VERSION ""

NS_ :

BS_:

BU_: a_box Charger OrionBMS DAQ

BO_ 2348816708 can2_precharge_hb: 2 a_box
 SG_ BMS : 8|8@1+ (1,0) [0|0] "" Vector__XXX
 SG_ IMD : 0|8@1+ (1,0) [0|0] "" Vector__XXX

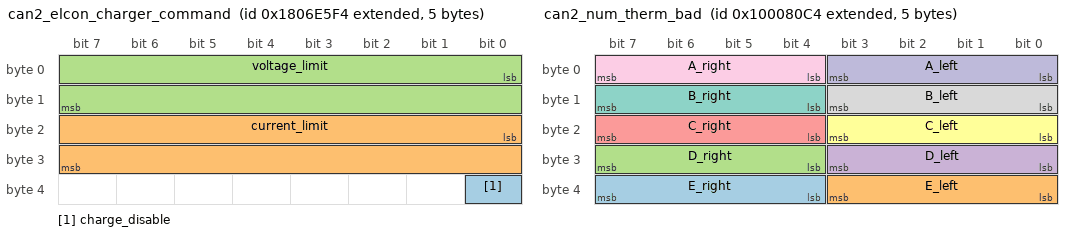
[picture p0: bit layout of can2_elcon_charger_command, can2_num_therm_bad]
BO_ 2550588916 can2_elcon_charger_command: 5 a_box
 SG_ charge_disable : 32|1@1+ (1,0) [0|0] "" Vector__XXX
 SG_ current_limit : 16|16@1+ (0.1,0) [0|0] "A" Vector__XXX
 SG_ voltage_limit : 0|16@1+ (0.1,0) [0|0] "V" Vector__XXX

BO_ 2415952068 can2_num_therm_bad: 5 a_box
 SG_ E_right : 36|4@1+ (1,0) [0|0] "" Vector__XXX
 SG_ E_left : 32|4@1+ (1,0) [0|0] "" Vector__XXX
 SG_ D_right : 28|4@1+ (1,0) [0|0] "" Vector__XXX
 SG_ D_left : 24|4@1+ (1,0) [0|0] "" Vector__XXX
 SG_ C_right : 20|4@1+ (1,0) [0|0] "" Vector__XXX
 SG_ C_left : 16|4@1+ (1,0) [0|0] "" Vector__XXX
 SG_ B_right : 12|4@1+ (1,0) [0|0] "" Vector__XXX
 SG_ B_left : 8|4@1+ (1,0) [0|0] "" Vector__XXX
 SG_ A_right : 4|4@1+ (1,0) [0|0] "" Vector__XXX
 SG_ A_left : 0|4@1+ (1,0) [0|0] "" Vector__XXX

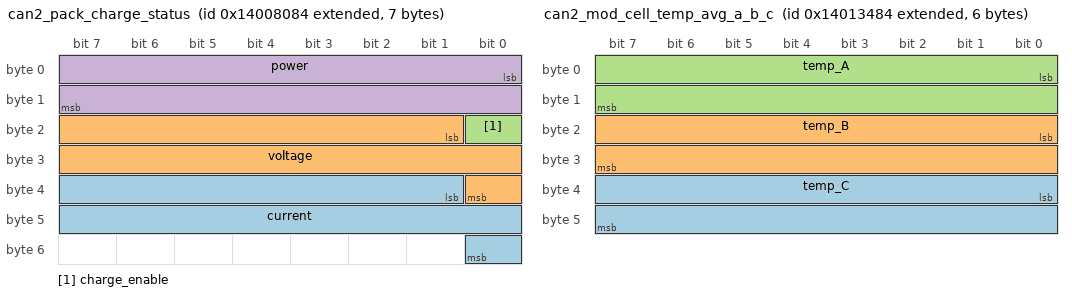
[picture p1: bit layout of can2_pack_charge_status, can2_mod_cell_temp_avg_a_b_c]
BO_ 2483060868 can2_pack_charge_status: 7 a_box
 SG_ current : 33|16@1+ (0.1,0) [0|0] "A" Vector__XXX
 SG_ voltage : 17|16@1+ (0.1,0) [0|0] "V" Vector__XXX
 SG_ charge_enable : 16|1@1+ (1,0) [0|0] "" Vector__XXX
 SG_ power : 0|16@1+ (1,0) [0|0] "W" Vector__XXX

BO_ 2349131268 can2_max_cell_temp: 2 a_box
 SG_ max_temp : 0|16@1- (0.1,0) [0|0] "" Vector__XXX

BO_ 2483106948 can2_mod_cell_temp_avg_a_b_c: 6 a_box
 SG_ temp_C : 32|16@1- (0.1,0) [0|0] "" Vector__XXX
 SG_ temp_B : 16|16@1- (0.1,0) [0|0] "" Vector__XXX
 SG_ temp_A : 0|16@1- (0.1,0) [0|0] "" Vector__XXX

BO_ 2483107012 can2_mod_cell_temp_avg_d_e: 4 a_box
 SG_ temp_E : 16|16@1- (0.1,0) [0|0] "" Vector__XXX
 SG_ temp_D : 0|16@1- (0.1,0) [0|0] "" Vector__XXX

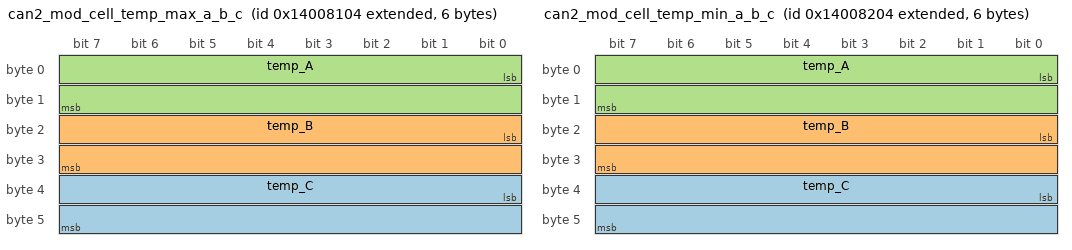
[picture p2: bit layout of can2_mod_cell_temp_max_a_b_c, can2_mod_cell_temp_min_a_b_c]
BO_ 2483060996 can2_mod_cell_temp_max_a_b_c: 6 a_box
 SG_ temp_C : 32|16@1- (0.1,0) [0|0] "" Vector__XXX
 SG_ temp_B : 16|16@1- (0.1,0) [0|0] "" Vector__XXX
 SG_ temp_A : 0|16@1- (0.1,0) [0|0] "" Vector__XXX

BO_ 2483061060 can2_mod_cell_temp_max_d_e: 4 a_box
 SG_ temp_E : 16|16@1- (0.1,0) [0|0] "" Vector__XXX
 SG_ temp_D : 0|16@1- (0.1,0) [0|0] "" Vector__XXX

BO_ 2483061252 can2_mod_cell_temp_min_a_b_c: 6 a_box
 SG_ temp_C : 32|16@1- (0.1,0) [0|0] "" Vector__XXX
 SG_ temp_B : 16|16@1- (0.1,0) [0|0] "" Vector__XXX
 SG_ temp_A : 0|16@1- (0.1,0) [0|0] "" Vector__XXX

BO_ 2483061316 can2_mod_cell_temp_min_d_e: 4 a_box
 SG_ temp_E : 16|16@1- (0.1,0) [0|0] "" Vector__XXX
 SG_ temp_D : 0|16@1- (0.1,0) [0|0] "" Vector__XXX

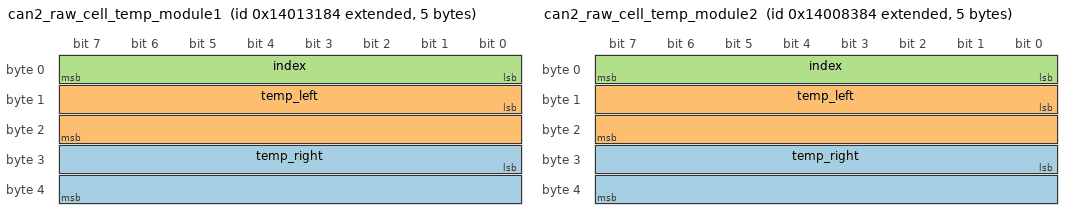
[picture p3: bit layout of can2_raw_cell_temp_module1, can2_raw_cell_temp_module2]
BO_ 2483106180 can2_raw_cell_temp_module1: 5 a_box
 SG_ temp_right : 24|16@1- (0.1,0) [0|0] "C" Vector__XXX
 SG_ temp_left : 8|16@1- (0.1,0) [0|0] "C" Vector__XXX
 SG_ index : 0|8@1+ (1,0) [0|0] "" Vector__XXX

BO_ 2483061636 can2_raw_cell_temp_module2: 5 a_box
 SG_ temp_right : 24|16@1- (0.1,0) [0|0] "C" Vector__XXX
 SG_ temp_left : 8|16@1- (0.1,0) [0|0] "C" Vector__XXX
 SG_ index : 0|8@1+ (1,0) [0|0] "" Vector__XXX

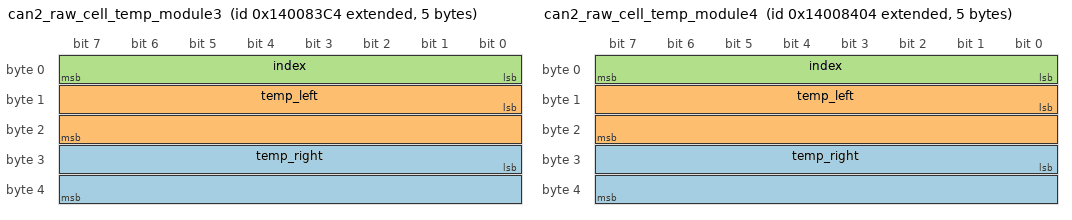
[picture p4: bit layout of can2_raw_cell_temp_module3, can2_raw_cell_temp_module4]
BO_ 2483061700 can2_raw_cell_temp_module3: 5 a_box
 SG_ temp_right : 24|16@1- (0.1,0) [0|0] "C" Vector__XXX
 SG_ temp_left : 8|16@1- (0.1,0) [0|0] "C" Vector__XXX
 SG_ index : 0|8@1+ (1,0) [0|0] "" Vector__XXX

BO_ 2483061764 can2_raw_cell_temp_module4: 5 a_box
 SG_ temp_right : 24|16@1- (0.1,0) [0|0] "C" Vector__XXX
 SG_ temp_left : 8|16@1- (0.1,0) [0|0] "C" Vector__XXX
 SG_ index : 0|8@1+ (1,0) [0|0] "" Vector__XXX

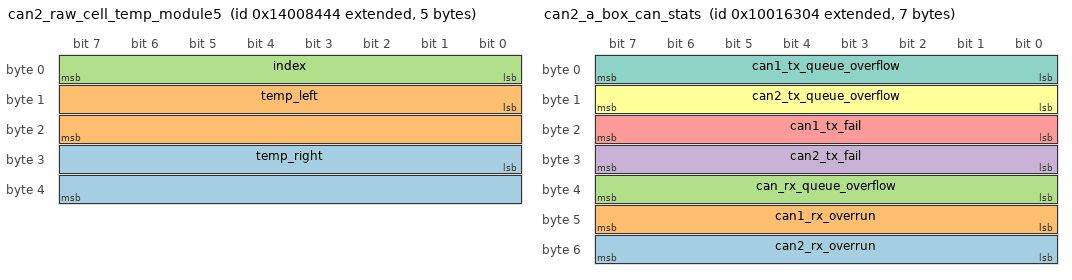
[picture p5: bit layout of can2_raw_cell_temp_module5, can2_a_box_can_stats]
BO_ 2483061828 can2_raw_cell_temp_module5: 5 a_box
 SG_ temp_right : 24|16@1- (0.1,0) [0|0] "C" Vector__XXX
 SG_ temp_left : 8|16@1- (0.1,0) [0|0] "C" Vector__XXX
 SG_ index : 0|8@1+ (1,0) [0|0] "" Vector__XXX

BO_ 2416009988 can2_a_box_can_stats: 7 a_box
 SG_ can2_rx_overrun : 48|8@1+ (1,0) [0|0] "" Vector__XXX
 SG_ can1_rx_overrun : 40|8@1+ (1,0) [0|0] "" Vector__XXX
 SG_ can_rx_queue_overflow : 32|8@1+ (1,0) [0|0] "" Vector__XXX
 SG_ can2_tx_fail : 24|8@1+ (1,0) [0|0] "" Vector__XXX
 SG_ can1_tx_fail : 16|8@1+ (1,0) [0|0] "" Vector__XXX
 SG_ can2_tx_queue_overflow : 8|8@1+ (1,0) [0|0] "" Vector__XXX
 SG_ can1_tx_queue_overflow : 0|8@1+ (1,0) [0|0] "" Vector__XXX

BO_ 2416010308 can2_i_sense: 4 a_box
 SG_ current_channel_2 : 16|16@1- (0.01,0) [0|0] "A" Vector__XXX
 SG_ current_channel_1 : 0|16@1- (0.01,0) [0|0] "A" Vector__XXX

BO_ 2550136772 daq_response_A_BOX_CCAN: 8 a_box
 SG_ daq_response : 0|64@1+ (1,0) [0|0] "" Vector__XXX

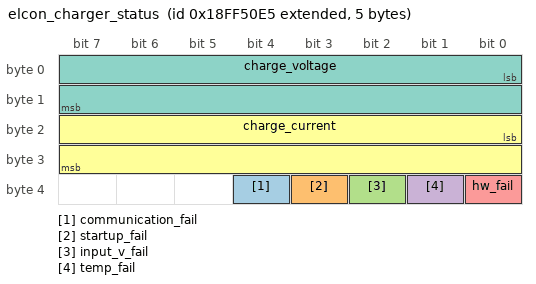
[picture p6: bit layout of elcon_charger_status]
BO_ 2566869221 elcon_charger_status: 5 Charger
 SG_ communication_fail : 36|1@1+ (1,0) [0|0] "" Vector__XXX
 SG_ startup_fail : 35|1@1+ (1,0) [0|0] "" Vector__XXX
 SG_ input_v_fail : 34|1@1+ (1,0) [0|0] "" Vector__XXX
 SG_ temp_fail : 33|1@1+ (1,0) [0|0] "" Vector__XXX
 SG_ hw_fail : 32|1@1+ (1,0) [0|0] "" Vector__XXX
 SG_ charge_current : 16|16@1+ (0.1,0) [0|0] "A" Vector__XXX
 SG_ charge_voltage : 0|16@1+ (0.1,0) [0|0] "V" Vector__XXX

BO_ 2483029688 orion_info_charger: 7 OrionBMS
 SG_ pack_soc : 48|8@1+ (0.5,0) [0|0] "%" Vector__XXX
 SG_ pack_ccl : 32|16@1+ (1,0) [0|0] "A" Vector__XXX
 SG_ pack_dcl : 16|16@1+ (1,0) [0|0] "A" Vector__XXX
 SG_ multi_output_1 : 15|1@1+ (1,0) [0|0] "" Vector__XXX
 SG_ multi_enable : 14|1@1+ (1,0) [0|0] "" Vector__XXX
 SG_ multi_output_4 : 13|1@1+ (1,0) [0|0] "" Vector__XXX
 SG_ multi_output_3 : 12|1@1+ (1,0) [0|0] "" Vector__XXX
 SG_ multi_output_2 : 11|1@1+ (1,0) [0|0] "" Vector__XXX
 SG_ reserved : 10|1@1+ (1,0) [0|0] "" Vector__XXX
 SG_ multi_input_3 : 9|1@1+ (1,0) [0|0] "" Vector__XXX
 SG_ multi_input_2 : 8|1@1+ (1,0) [0|0] "" Vector__XXX
 SG_ is_charging : 7|1@1+ (1,0) [0|0] "" Vector__XXX
 SG_ is_ready : 6|1@1+ (1,0) [0|0] "" Vector__XXX
 SG_ always_on : 5|1@1+ (1,0) [0|0] "" Vector__XXX
 SG_ multi_input : 4|1@1+ (1,0) [0|0] "" Vector__XXX
 SG_ dtc_status : 3|1@1+ (1,0) [0|0] "" Vector__XXX
 SG_ charger_safety : 2|1@1+ (1,0) [0|0] "" Vector__XXX
 SG_ charge_enable : 1|1@1+ (1,0) [0|0] "" Vector__XXX
 SG_ discharge_enable : 0|1@1+ (1,0) [0|0] "" Vector__XXX

BO_ 2483029752 orion_currents_volts_charger: 4 OrionBMS
 SG_ pack_voltage : 16|16@1+ (0.1,0) [0|0] "V" Vector__XXX
 SG_ pack_current : 0|16@1- (0.1,0) [0|0] "A" Vector__XXX

BO_ 2348812088 orion_errors_charger: 4 OrionBMS
 SG_ charge_limit_enforce : 31|1@1+ (1,0) [0|0] "" Vector__XXX
 SG_ input_psu : 30|1@1+ (1,0) [0|0] "" Vector__XXX
 SG_ hv_isolation : 29|1@1+ (1,0) [0|0] "" Vector__XXX
 SG_ redundant_psu : 28|1@1+ (1,0) [0|0] "" Vector__XXX
 SG_ external_comms : 27|1@1+ (1,0) [0|0] "" Vector__XXX
 SG_ thermistor : 26|1@1+ (1,0) [0|0] "" Vector__XXX
 SG_ fan_monitor : 25|1@1+ (1,0) [0|0] "" Vector__XXX
 SG_ weak_pack : 24|1@1+ (1,0) [0|0] "" Vector__XXX
 SG_ cell_asic : 23|1@1+ (1,0) [0|0] "" Vector__XXX
 SG_ max_cellv_o5v : 22|1@1+ (1,0) [0|0] "" Vector__XXX
 SG_ current_sensor : 21|1@1+ (1,0) [0|0] "" Vector__XXX
 SG_ open_wire : 20|1@1+ (1,0) [0|0] "" Vector__XXX
 SG_ low_cellv : 19|1@1+ (1,0) [0|0] "" Vector__XXX
 SG_ weak_cell : 18|1@1+ (1,0) [0|0] "" Vector__XXX
 SG_ cell_balancing_foff : 17|1@1+ (1,0) [0|0] "" Vector__XXX
 SG_ internal_comms : 16|1@1+ (1,0) [0|0] "" Vector__XXX
 SG_ reserved7 : 15|1@1+ (1,0) [0|0] "" Vector__XXX
 SG_ reserved6 : 14|1@1+ (1,0) [0|0] "" Vector__XXX
 SG_ reserved5 : 13|1@1+ (1,0) [0|0] "" Vector__XXX
 SG_ reserved4 : 12|1@1+ (1,0) [0|0] "" Vector__XXX
 SG_ reserved3 : 11|1@1+ (1,0) [0|0] "" Vector__XXX
 SG_ reserved2 : 10|1@1+ (1,0) [0|0] "" Vector__XXX
 SG_ reserved1 : 9|1@1+ (1,0) [0|0] "" Vector__XXX
 SG_ reserved0 : 8|1@1+ (1,0) [0|0] "" Vector__XXX
 SG_ pack_overheat : 7|1@1+ (1,0) [0|0] "" Vector__XXX
 SG_ min_cellv_low : 6|1@1+ (1,0) [0|0] "" Vector__XXX
 SG_ max_cellv_high : 5|1@1+ (1,0) [0|0] "" Vector__XXX
 SG_ software : 4|1@1+ (1,0) [0|0] "" Vector__XXX
 SG_ heatsink_thermistor : 3|1@1+ (1,0) [0|0] "" Vector__XXX
 SG_ internal_hardware : 2|1@1+ (1,0) [0|0] "" Vector__XXX
 SG_ charger_safety_relay : 1|1@1+ (1,0) [0|0] "" Vector__XXX
 SG_ discharge_limit_enforce : 0|1@1+ (1,0) [0|0] "" Vector__XXX

BO_ 2483028274 daq_command_A_BOX_CCAN: 8 DAQ
 SG_ daq_command : 0|64@1+ (1,0) [0|0] "" Vector__XXX

CM_ BO_ 2348816708 "heart beat for precharge";
CM_ SG_ 2348816708 BMS "Fault State of BMS";
CM_ SG_ 2348816708 IMD "Fault State of IMD";
CM_ BO_ 2550588916 "Charge voltage and current request to ELCON charger";
CM_ SG_ 2550588916 charge_disable "Disable charging";
CM_ SG_ 2550588916 current_limit "Requested charge current";
CM_ SG_ 2550588916 voltage_limit "Requested charge voltage";
CM_ BO_ 2415952068 "Number of wonky thermistors on pack";
CM_ SG_ 2415952068 E_right "Number of thermistors > 1.5v";
CM_ SG_ 2415952068 E_left "Number of thermistors > 1.5v";
CM_ SG_ 2415952068 D_right "Number of thermistors > 1.5v";
CM_ SG_ 2415952068 D_left "Number of thermistors > 1.5v";
CM_ SG_ 2415952068 C_right "Number of thermistors > 1.5v";
CM_ SG_ 2415952068 C_left "Number of thermistors > 1.5v";
CM_ SG_ 2415952068 B_right "Number of thermistors > 1.5v";
CM_ SG_ 2415952068 B_left "Number of thermistors > 1.5v";
CM_ SG_ 2415952068 A_right "Number of thermistors > 1.5v";
CM_ SG_ 2415952068 A_left "Number of thermistors > 1.5v";
CM_ BO_ 2483060868 "Statistics about current charge cycle";
CM_ SG_ 2483060868 current "Instantaneous charge current";
CM_ SG_ 2483060868 voltage "Instantaneous charge voltage";
CM_ SG_ 2483060868 charge_enable "Charge mode enabled";
CM_ SG_ 2483060868 power "Instantaneous charge power";
CM_ BO_ 2349131268 "maximum cell temperature for the whole pack";
CM_ BO_ 2483106948 "Average cell temperature for each module";
CM_ BO_ 2483107012 "Average cell temperature for each module";
CM_ BO_ 2483060996 "Max cell temperature for a, b, and c";
CM_ BO_ 2483061060 "Max cell temperature for d and e";
CM_ BO_ 2483061252 "Min cell temperature for each a, b, and c";
CM_ BO_ 2483061316 "Min cell temperature for each d and e";
CM_ BO_ 2483106180 "Raw cell temperature for each module of thermistor at index";
CM_ BO_ 2483061636 "Raw cell temperature for each module of thermistor at index";
CM_ BO_ 2483061700 "Raw cell temperature for each module of thermistor at index";
CM_ BO_ 2483061764 "Raw cell temperature for each module of thermistor at index";
CM_ BO_ 2483061828 "Raw cell temperature for each module of thermistor at index";
CM_ BO_ 2416009988 "CAN diagnostics";
CM_ SG_ 2416009988 can2_rx_overrun "CCAN (Charger CAN) Rx FIFO overrun count";
CM_ SG_ 2416009988 can1_rx_overrun "VCAN Rx FIFO overrun count";
CM_ SG_ 2416009988 can_rx_queue_overflow "CAN Rx queue overflow count";
CM_ SG_ 2416009988 can2_tx_fail "CAN Tx fail count for CCAN (Charger CAN) (due to timeout in mailbox)";
CM_ SG_ 2416009988 can1_tx_fail "CAN Tx fail count for VCAN (due to timeout in mailbox)";
CM_ SG_ 2416009988 can2_tx_queue_overflow "CCAN (Charger CAN) Tx queue overflow count";
CM_ SG_ 2416009988 can1_tx_queue_overflow "VCAN Tx queue overflow count";
CM_ BO_ 2416010308 "Current sense value for channel 1 and channel 2 of pack current sensor";
CM_ SG_ 2416010308 current_channel_2 "Channel 2 used to measure higher pack currents, lower fidelity than channel 1";
CM_ SG_ 2416010308 current_channel_1 "Channel 1 used for BSPD circuit, Higher fidelity, but maxes out at a low amperage";
CM_ BO_ 2550136772 "daq response from node A_BOX";
CM_ BO_ 2566869221 "Realtime charger status";
CM_ SG_ 2566869221 communication_fail " 5s timeout from communication failure";
CM_ SG_ 2566869221 startup_fail "Startup voltage detection failure";
CM_ SG_ 2566869221 input_v_fail "Input voltage failure";
CM_ SG_ 2566869221 temp_fail "Temperature failure";
CM_ SG_ 2566869221 hw_fail "Hardware failure";
CM_ BO_ 2483029688 "charge, State, Current/voltage limits";
CM_ SG_ 2483029688 pack_soc "Pack State of Charge";
CM_ SG_ 2483029688 pack_ccl "Pack charge current limit";
CM_ SG_ 2483029688 pack_dcl "Pack discharge current limit";
CM_ SG_ 2483029688 multi_output_1 "Orion multi purpose output status - unused";
CM_ SG_ 2483029688 multi_enable "Orion multi purpose output with watchdog functionality - unused";
CM_ SG_ 2483029688 multi_output_4 "Orion multi purpose output status - unused";
CM_ SG_ 2483029688 multi_output_3 "Orion multi purpose output status - unused";
CM_ SG_ 2483029688 multi_output_2 "Orion multi purpose output status - unused";
CM_ SG_ 2483029688 multi_input_3 "Orion multi purpose input status - unused";
CM_ SG_ 2483029688 multi_input_2 "Orion multi purpose input status - unused";
CM_ SG_ 2483029688 is_charging "Orion is in \"CHARGE\" mode - controlled by charge power pin";
CM_ SG_ 2483029688 is_ready "Orion is in \"READY\" (discharge) mode";
CM_ SG_ 2483029688 always_on "Orion's low power sleep input is configured";
CM_ SG_ 2483029688 multi_input "Orion multi purpose input status - unused";
CM_ SG_ 2483029688 dtc_status "General error status of OrionBMS";
CM_ SG_ 2483029688 charger_safety "Charger BMS SDC control input - allows current to flow into pack";
CM_ SG_ 2483029688 charge_enable "Permits intermittent charging of pack - AKA Regen (Not currently used)";
CM_ SG_ 2483029688 discharge_enable "Main BMS SDC control input - allows current to be drawn from pack";
CM_ BO_ 2483029752 "Pack current + voltage";
CM_ BO_ 2348812088 "Pack DTC (Diagnostic Trouble Code) Flags";
CM_ SG_ 2348812088 charge_limit_enforce "The orion pack charge curent limit was exceeded - set if violation occured with \"charge enable\" relay";
CM_ SG_ 2348812088 input_psu "Orion is not recieving a stable power supply between 9v and 30v";
CM_ SG_ 2348812088 hv_isolation "BMS has detected a breakdown in HV/LV isolation";
CM_ SG_ 2348812088 redundant_psu "The BMS has lost the \"always on\" power supply, meaning it is no longer redundant (must be configured)";
CM_ SG_ 2348812088 external_comms "Expected CAN messages (must be configured) have not been recieved";
CM_ SG_ 2348812088 thermistor "A thermistor reading has fallen out of it expected operating range";
CM_ SG_ 2348812088 fan_monitor "Voltage on fan monitor (multi-input-3) goes outside provided threshold (if enabled)";
CM_ SG_ 2348812088 weak_pack "Pack state of health estimation falls below provided threshold";
CM_ SG_ 2348812088 cell_asic "Orion has detected a communication problem with its cell voltage measurement circuitry - check fault subcode";
CM_ SG_ 2348812088 max_cellv_o5v "A cell in the pack has been detected to have a cell voltage over 5V";
CM_ SG_ 2348812088 current_sensor "BMS has detected a problem with the current sensor (check fault subcodes)";
CM_ SG_ 2348812088 open_wire "Cell tap wire is either weakly connected or fully disconnected";
CM_ SG_ 2348812088 low_cellv "One or more cells have an extremely low cell voltage (likely dead or wiring problem) (threshold configurable)";
CM_ SG_ 2348812088 weak_cell "Orion has either detected a weak cell within the pack, or a cell that is too far out of balance";
CM_ SG_ 2348812088 cell_balancing_foff "At least one cell balancing circuit is not working";
CM_ SG_ 2348812088 internal_comms "Orion cannot communicate with its isolated cell voltage measurement hardware";
CM_ SG_ 2348812088 pack_overheat "Pack temp has exceeded its max allowable value for >30s";
CM_ SG_ 2348812088 min_cellv_low "An individual cell has gone under its minimum allowable voltage";
CM_ SG_ 2348812088 max_cellv_high "An individual cell has exceeded its maximum allowable voltage";
CM_ SG_ 2348812088 software "Bug in internal software led to invalid operation";
CM_ SG_ 2348812088 heatsink_thermistor "Orion can't detect it's internal temperature";
CM_ SG_ 2348812088 internal_hardware "Orion has detected a hardware failure within itself";
CM_ SG_ 2348812088 charger_safety_relay "Charge Current limit exceeded - set if violation occured with \"charger safety\" relay";
CM_ SG_ 2348812088 discharge_limit_enforce "Discharge current limit exceed";
CM_ BO_ 2483028274 "daq command for node A_BOX_CCAN";
